# SMS0_WDTCTRL_0_RTI register map
Vendor: Texas Instruments
Peripheral module from a debugger description file (folder am62P).
Registers are 32-bit, read-write, reset 0x0 unless marked. A register's access mark holds for its fields unless they carry their own. Offsets are as the file gives them; lines under a group give offsets from that group; [hi:lo] are bit positions; {n}, {i} and the like mark numbered series; 'fields as' and 'values as' point back to an identical list; <NAME> marks a mode.

## SMS0_WDTCTRL_0_RTI
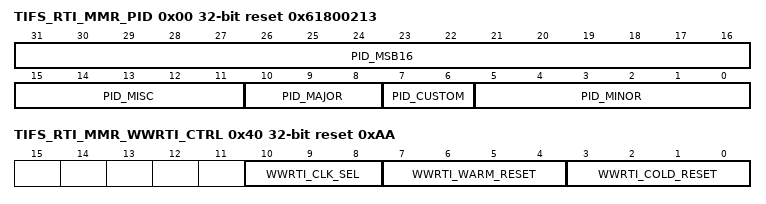
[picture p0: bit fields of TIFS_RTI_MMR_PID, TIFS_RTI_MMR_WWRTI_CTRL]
0x00 TIFS_RTI_MMR_PID ro reset 0x61800213
  [31:16] PID_MSB16, [15:11] PID_MISC, [10:8] PID_MAJOR, [7:6] PID_CUSTOM, [5:0] PID_MINOR
0x20 TIFS_RTI_MMR_LOCK0_KICK0
  [31:0] LOCK0_KICK0 — - KICK0 component
0x24 TIFS_RTI_MMR_LOCK0_KICK1
  [31:0] LOCK0_KICK1 — - KICK1 component
0x40 TIFS_RTI_MMR_WWRTI_CTRL reset 0xAA
  [10:8] WWRTI_CLK_SEL, [7:4] WWRTI_WARM_RESET, [3:0] WWRTI_COLD_RESET
0x50 TIFS_RTI_MMR_WWRTI_CLOCK_CTRL reset 0xA
  [3:0] WWRTI_CLK_CTRL
